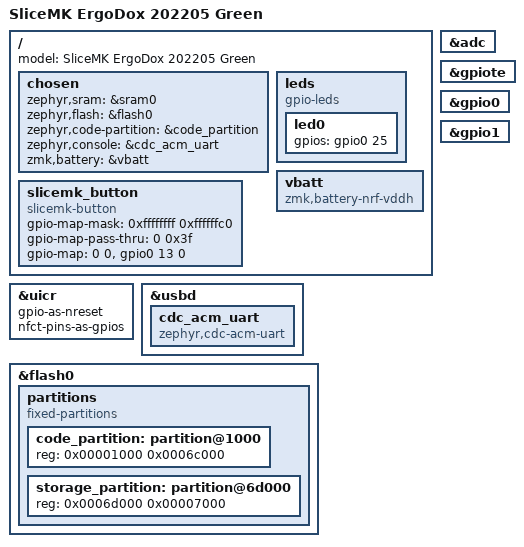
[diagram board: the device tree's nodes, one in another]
/dts-v1/;
#include <nordic/nrf52833_qiaa.dtsi>

/ {
    model = "SliceMK ErgoDox 202205 Green";

    chosen {
        zephyr,sram = &sram0;
        zephyr,flash = &flash0;
        zephyr,code-partition = &code_partition;
        zephyr,console = &cdc_acm_uart;

        zmk,battery = &vbatt;
    };

    leds {
        compatible = "gpio-leds";
        led0: led0 {
            gpios = <&gpio0 25 GPIO_ACTIVE_HIGH>;
        };
    };

    // Use VDDHDIV5 for battery voltage.
    vbatt: vbatt {
        compatible = "zmk,battery-nrf-vddh";
    };

    slicemk_button: slicemk_button {
        compatible = "slicemk-button";
        #gpio-cells = <2>;
        gpio-map-mask = <0xffffffff 0xffffffc0>;
        gpio-map-pass-thru = <0 0x3f>;
        gpio-map = <0 0 &gpio0 13 0>;
    };
};

&adc {
    status = "okay";
};

&gpiote {
    status = "okay";
};

&gpio0 {
    status = "okay";
};

&gpio1 {
    status = "okay";
};

&uicr {
	gpio-as-nreset;
	nfct-pins-as-gpios;
};

&usbd {
    status = "okay";
    cdc_acm_uart: cdc_acm_uart {
        compatible = "zephyr,cdc-acm-uart";
    };
};

&flash0 {
    partitions {
        compatible = "fixed-partitions";
        #address-cells = <1>;
        #size-cells = <1>;

        code_partition: partition@1000 {
            reg = <0x00001000 0x0006c000>;
        };

        storage_partition: partition@6d000 {
            reg = <0x0006d000 0x00007000>;
        };
    };
};
